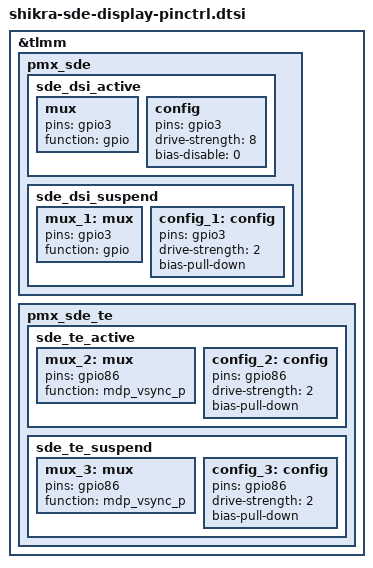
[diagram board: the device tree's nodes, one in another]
// SPDX-License-Identifier: BSD-3-Clause
/*
 * Copyright (c) Qualcomm Technologies, Inc. and/or its subsidiaries.
 */

&tlmm {
	pmx_sde: pmx_sde {
		sde_dsi_active: sde_dsi_active {
			mux: mux {
				pins = "gpio3";
				function = "gpio";
			};

			config: config {
				pins = "gpio3";
				drive-strength = <8>;   /* 8 mA */
				bias-disable = <0>;   /* no pull */
			};
		};

		sde_dsi_suspend: sde_dsi_suspend {
			mux_1: mux {
				pins = "gpio3";
				function = "gpio";
			};

			config_1: config {
				pins = "gpio3";
				drive-strength = <2>;   /* 2 mA */
				bias-pull-down;         /* PULL DOWN */
			};
		};
	};

	pmx_sde_te: pmx_sde_te {
		sde_te_active: sde_te_active {
			mux_2: mux {
				pins = "gpio86";
				function = "mdp_vsync_p";
			};

			config_2: config {
				pins = "gpio86";
				drive-strength = <2>;   /* 2 mA */
				bias-pull-down;         /* PULL DOWN */
			};
		};

		sde_te_suspend: sde_te_suspend {
			mux_3: mux {
				pins = "gpio86";
				function = "mdp_vsync_p";
			};

			config_3: config {
				pins = "gpio86";
				drive-strength = <2>;   /* 2 mA */
				bias-pull-down;         /* PULL DOWN */
			};
		};
	};
};
